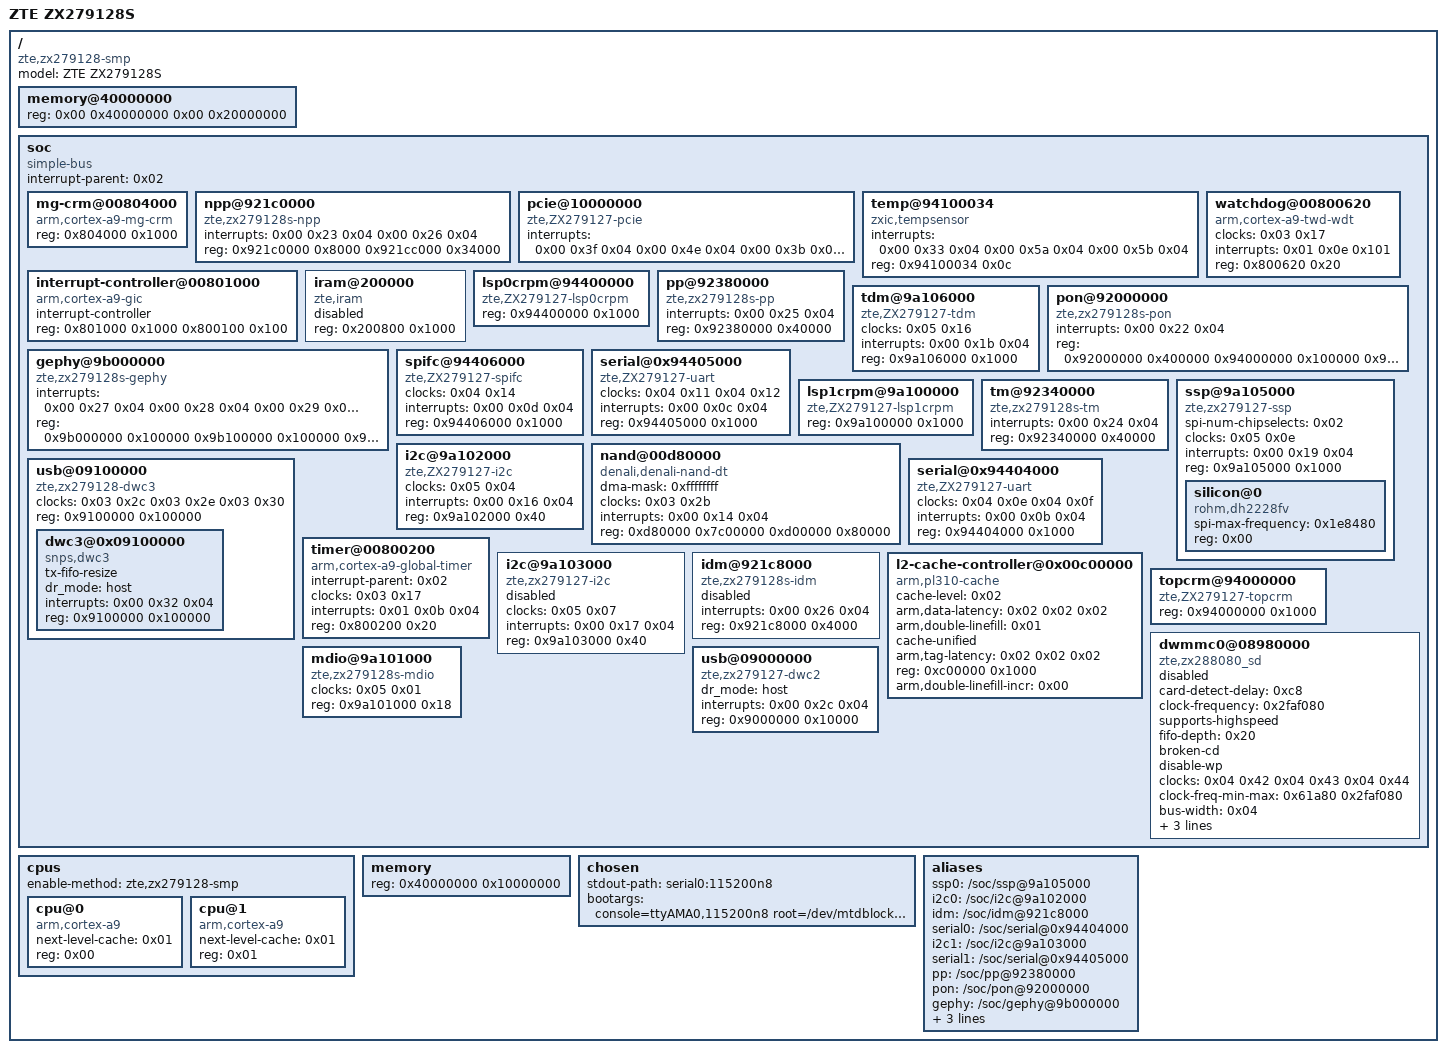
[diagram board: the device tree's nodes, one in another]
/dts-v1/;

/ {
	#address-cells = <0x01>;
	#size-cells = <0x01>;
	model = "ZTE ZX279128S";
	compatible = "zte,zx279128-smp";

	memory@40000000 {
		device_type = "memory";
		reg = <0x00 0x40000000 0x00 0x20000000>;
	};

	soc {
		#address-cells = <0x01>;
		ranges;
		interrupt-parent = <0x02>;
		#size-cells = <0x01>;
		compatible = "simple-bus";

		mg-crm@00804000 {
			reg = <0x804000 0x1000>;
			compatible = "arm,cortex-a9-mg-crm";
		};

		npp@921c0000 {
			interrupts = <0x00 0x23 0x04 0x00 0x26 0x04>;
			status = "okay";
			reg = <0x921c0000 0x8000 0x921cc000 0x34000>;
			compatible = "zte,zx279128s-npp";
		};

		pcie@10000000 {
			interrupts = <0x00 0x3f 0x04 0x00 0x4e 0x04 0x00 0x3b 0x04 0x00 0x4a 0x04>;
			status = "okay";
			compatible = "zte,ZX279127-pcie";
		};

		temp@94100034 {
			interrupts = <0x00 0x33 0x04 0x00 0x5a 0x04 0x00 0x5b 0x04>;
			status = "okay";
			reg = <0x94100034 0x0c>;
			compatible = "zxic,tempsensor";
		};

		interrupt-controller@00801000 {
			#address-cells = <0x01>;
			linux,phandle = <0x02>;
			#interrupt-cells = <0x03>;
			phandle = <0x02>;
			#size-cells = <0x01>;
			interrupt-controller;
			reg = <0x801000 0x1000 0x800100 0x100>;
			compatible = "arm,cortex-a9-gic";
		};

		watchdog@00800620 {
			clocks = <0x03 0x17>;
			interrupts = <0x01 0x0e 0x101>;
			status = "okay";
			reg = <0x800620 0x20>;
			compatible = "arm,cortex-a9-twd-wdt";
		};

		iram@200000 {
			status = "enable";
			reg = <0x200800 0x1000>;
			compatible = "zte,iram";
		};

		lsp0crpm@94400000 {
			linux,phandle = <0x04>;
			phandle = <0x04>;
			#clock-cells = <0x01>;
			reg = <0x94400000 0x1000>;
			compatible = "zte,ZX279127-lsp0crpm";
		};

		pp@92380000 {
			interrupts = <0x00 0x25 0x04>;
			status = "okay";
			reg = <0x92380000 0x40000>;
			compatible = "zte,zx279128s-pp";
		};

		tdm@9a106000 {
			clocks = <0x05 0x16>;
			interrupts = <0x00 0x1b 0x04>;
			status = "okay";
			reg = <0x9a106000 0x1000>;
			compatible = "zte,ZX279127-tdm";
		};

		pon@92000000 {
			interrupts = <0x00 0x22 0x04>;
			status = "okay";
			reg = <0x92000000 0x400000 0x94000000 0x100000 0x94100000 0x100000 0x94200000 0x100000 0x9fe00000 0x100000>;
			compatible = "zte,zx279128s-pon";
		};

		gephy@9b000000 {
			interrupts = <0x00 0x27 0x04 0x00 0x28 0x04 0x00 0x29 0x04 0x00 0x2a 0x04>;
			status = "okay";
			reg = <0x9b000000 0x100000 0x9b100000 0x100000 0x9b200000 0x100000 0x9b300000 0x100000>;
			compatible = "zte,zx279128s-gephy";
		};

		spifc@94406000 {
			#address-cells = <0x01>;
			reg-names = "spifc_reg";
			clocks = <0x04 0x14>;
			interrupts = <0x00 0x0d 0x04>;
			#size-cells = <0x01>;
			status = "okay";
			reg = <0x94406000 0x1000>;
			compatible = "zte,ZX279127-spifc";
		};

		serial@0x94405000 {
			clocks = <0x04 0x11 0x04 0x12>;
			interrupts = <0x00 0x0c 0x04>;
			clock-names = "uartclk", "apb_pclk";
			status = "okay";
			reg = <0x94405000 0x1000>;
			compatible = "zte,ZX279127-uart";
		};

		lsp1crpm@9a100000 {
			linux,phandle = <0x05>;
			phandle = <0x05>;
			#clock-cells = <0x01>;
			reg = <0x9a100000 0x1000>;
			compatible = "zte,ZX279127-lsp1crpm";
		};

		tm@92340000 {
			interrupts = <0x00 0x24 0x04>;
			status = "okay";
			reg = <0x92340000 0x40000>;
			compatible = "zte,zx279128s-tm";
		};

		ssp@9a105000 {
			spi-num-chipselects = <0x02>;
			clocks = <0x05 0x0e>;
			interrupts = <0x00 0x19 0x04>;
			status = "okay";
			reg = <0x9a105000 0x1000>;
			compatible = "zte,zx279127-ssp";

			silicon@0 {
				spi-max-frequency = <0x1e8480>;
				reg = <0x00>;
				compatible = "rohm,dh2228fv";
			};
		};

		i2c@9a102000 {
			clocks = <0x05 0x04>;
			interrupts = <0x00 0x16 0x04>;
			status = "okay";
			reg = <0x9a102000 0x40>;
			compatible = "zte,ZX279127-i2c";
		};

		nand@00d80000 {
			#address-cells = <0x01>;
			reg-names = "nand_data", "denali_reg";
			dma-mask = <0xffffffff>;
			clocks = <0x03 0x2b>;
			interrupts = <0x00 0x14 0x04>;
			#size-cells = <0x01>;
			status = "okay";
			reg = <0xd80000 0x7c00000 0xd00000 0x80000>;
			compatible = "denali,denali-nand-dt";
		};

		usb@09100000 {
			#address-cells = <0x01>;
			ranges;
			clocks = <0x03 0x2c 0x03 0x2e 0x03 0x30>;
			#size-cells = <0x01>;
			clock-names = "usb_bus_clk", "usb_ref_clk0", "usb_ref_clk1";
			status = "okay";
			reg = <0x9100000 0x100000>;
			compatible = "zte,zx279128-dwc3";

			dwc3@0x09100000 {
				tx-fifo-resize;
				dr_mode = "host";
				interrupts = <0x00 0x32 0x04>;
				reg = <0x9100000 0x100000>;
				compatible = "snps,dwc3";
			};
		};

		serial@0x94404000 {
			clocks = <0x04 0x0e 0x04 0x0f>;
			interrupts = <0x00 0x0b 0x04>;
			clock-names = "uartclk", "apb_pclk";
			status = "okay";
			reg = <0x94404000 0x1000>;
			compatible = "zte,ZX279127-uart";
		};

		timer@00800200 {
			interrupt-parent = <0x02>;
			clocks = <0x03 0x17>;
			interrupts = <0x01 0x0b 0x04>;
			reg = <0x800200 0x20>;
			compatible = "arm,cortex-a9-global-timer";
		};

		i2c@9a103000 {
			clocks = <0x05 0x07>;
			interrupts = <0x00 0x17 0x04>;
			status = "disabled";
			reg = <0x9a103000 0x40>;
			compatible = "zte,zx279127-i2c";
		};

		idm@921c8000 {
			interrupts = <0x00 0x26 0x04>;
			status = "disabled";
			reg = <0x921c8000 0x4000>;
			compatible = "zte,zx279128s-idm";
		};

		l2-cache-controller@0x00c00000 {
			linux,phandle = <0x01>;
			cache-level = <0x02>;
			arm,data-latency = <0x02 0x02 0x02>;
			arm,double-linefill = <0x01>;
			cache-unified;
			phandle = <0x01>;
			arm,tag-latency = <0x02 0x02 0x02>;
			reg = <0xc00000 0x1000>;
			arm,double-linefill-incr = <0x00>;
			compatible = "arm,pl310-cache";
		};

		topcrm@94000000 {
			linux,phandle = <0x03>;
			phandle = <0x03>;
			#clock-cells = <0x01>;
			reg = <0x94000000 0x1000>;
			compatible = "zte,ZX279127-topcrm", "syscon";
		};

		dwmmc0@08980000 {
			#address-cells = <0x01>;
			card-detect-delay = <0xc8>;
			clock-frequency = <0x2faf080>;
			supports-highspeed;
			fifo-depth = <0x20>;
			broken-cd;
			disable-wp;
			clocks = <0x04 0x42 0x04 0x43 0x04 0x44>;
			clock-freq-min-max = <0x61a80 0x2faf080>;
			bus-width = <0x04>;
			interrupts = <0x00 0x2b 0x04>;
			#size-cells = <0x01>;
			clock-names = "fb_sdmmc_work_clk", "fb_sdmmc_ahb_clk", "fb_sdmmc_cdet_clk";
			num-slots = <0x01>;
			status = "disable";
			reg = <0x8980000 0x1000>;
			compatible = "zte,zx288080_sd";
		};

		mdio@9a101000 {
			clocks = <0x05 0x01>;
			status = "okay";
			reg = <0x9a101000 0x18>;
			compatible = "zte,zx279128s-mdio";
		};

		usb@09000000 {
			dr_mode = "host";
			interrupts = <0x00 0x2c 0x04>;
			status = "okay";
			reg = <0x9000000 0x10000>;
			compatible = "zte,zx279127-dwc2";
		};
	};

	cpus {
		#address-cells = <0x01>;
		enable-method = "zte,zx279128-smp";
		#size-cells = <0x00>;

		cpu@0 {
			device_type = "cpu";
			next-level-cache = <0x01>;
			reg = <0x00>;
			compatible = "arm,cortex-a9";
		};

		cpu@1 {
			device_type = "cpu";
			next-level-cache = <0x01>;
			reg = <0x01>;
			compatible = "arm,cortex-a9";
		};
	};

	memory {
		device_type = "memory";
		reg = <0x40000000 0x10000000>;
	};

	chosen {
		stdout-path = "serial0:115200n8";
		bootargs = "console=ttyAMA0,115200n8 root=/dev/mtdblock9 ro rootfstype=jffs2 mem=256M; U-Boot V9.0.11P10N2 20230111141616 0x1a00000 0x0 0x8f 0x83";
	};

	aliases {
		ssp0 = "/soc/ssp@9a105000";
		i2c0 = "/soc/i2c@9a102000";
		idm = "/soc/idm@921c8000";
		serial0 = "/soc/serial@0x94404000";
		i2c1 = "/soc/i2c@9a103000";
		serial1 = "/soc/serial@0x94405000";
		pp = "/soc/pp@92380000";
		pon = "/soc/pon@92000000";
		gephy = "/soc/gephy@9b000000";
		tm = "/soc/tm@92340000";
		pcie = "/soc/pcie@10000000";
		npp = "/soc/npp@921c0000";
	};
};
